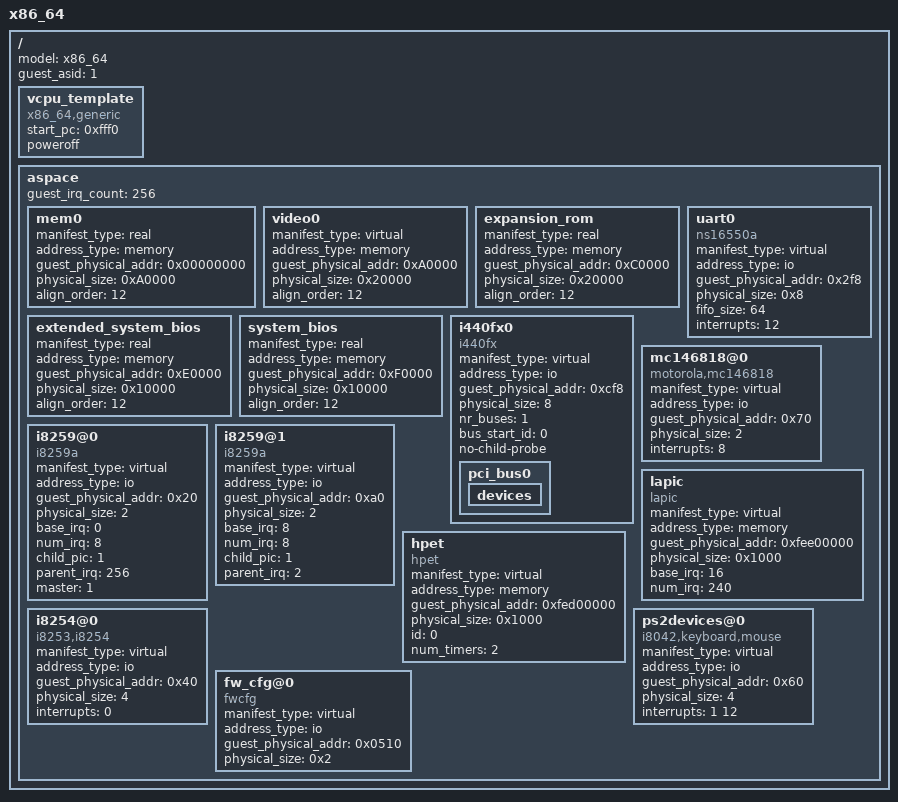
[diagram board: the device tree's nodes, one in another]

/dts-v1/;

/ {
	model = "x86_64";
	device_type = "guest";
	guest_asid = <1>;

	vcpu_template {
		device_type = "vcpu";
		compatible = "x86_64,generic";
		start_pc = <0xfff0>;
		poweroff;
	};

	aspace {
		guest_irq_count = <256>;
		/*
		 * Memory Regions
		 *
		 *   0 - 640 KiB => Accessible RAM (old DOS area)
		 * 640 - 768 KiB => Legacy Video card memory
		 * 768 - 896 KiB => Expansion area (Old peripheral card ROM)
		 * 896 - 960 KiB => Extended System BIOS (SeaBIOS links here 0xexxxx)
		 * 960 -   1 MiB => System BIOS
		 * 1MiB -  4GiB-16bytes => RAM (High Memory)
		 * 4GiB-16 byte => RESET VECTOR (0xFFFFFFF0) This jumps to System BIOS (normal/extented).
		 */

		/*
		 *	0x00000000 	0x000003FF 	1 KiB 		Real Mode IVT (Interrupt Vector Table)
		 *	0x00000400 	0x000004FF 	256 bytes 	BDA (BIOS data area)
		 *	0x00000500 	0x00007BFF 	30 KiB 		Conventional memory
		 *	0x00007C00  	0x00007DFF 	512 bytes 	OS BootSector
		 *	0x00007E00 	0x0007FFFF 	480.5 KiB 	Conventional memory
		 *	0x00080000 	0x0009FBFF 	~120 KiB 	Conventional memory
		 *	0x0009FC00 	0x0009FFFF 	1 KiB 		EBDA (Extended BIOS Data Area)
		 */
		mem0 {
			manifest_type = "real";
			address_type = "memory";
			guest_physical_addr = <0x00000000>;
			physical_size = <0xA0000>;
			device_type = "alloced_ram";
			align_order = <12>; /* 4K alignment */
		};

		video0 {
			manifest_type = "virtual";
			address_type = "memory";
			guest_physical_addr = <0xA0000>;
			physical_size = <0x20000>;
			device_type = "alloced_ram";
			align_order = <12>;
		};

		/* ROMs for old peripheral cards */
		expansion_rom {
			manifest_type = "real";
			address_type = "memory";
			guest_physical_addr = <0xC0000>;
			physical_size = <0x20000>;
			device_type = "alloced_rom";
			align_order = <12>;
		};

		/* Map in protected mode where BIOS will jump, Total 128K for BIOS */
		extended_system_bios {
			manifest_type = "real";
			address_type = "memory";
			guest_physical_addr = <0xE0000>;
			physical_size = <0x10000>; /* 64K extended BIOS */
			device_type = "alloced_rom";
			align_order = <12>; /* 4K aligns */
		};

		system_bios {
			manifest_type = "real";
			address_type = "memory";
			guest_physical_addr = <0xF0000>;
			physical_size = <0x10000>; /* 64K system BIOS */
			device_type = "alloced_rom";
			align_order = <12>;
		};

		uart0 {
			device_type = "serial";
			compatible = "ns16550a";
			manifest_type = "virtual";
			address_type = "io";
			guest_physical_addr = <0x2f8>;
			physical_size = <0x8>;
			fifo_size = <64>;
			interrupts = <12>;
		};

		i440fx0 {
			device_type = "pci-host-controller";
			compatible = "i440fx";
			manifest_type = "virtual";
			address_type = "io";
			guest_physical_addr = <0xcf8>;
			physical_size = <8>;
			nr_buses = <1>;
			bus_start_id = <0>;
			no-child-probe;

			pci_bus0 {
				devices {
				};
			};
		};

		mc146818@0 {
			device_type = "rtc";
			compatible = "motorola,mc146818";
			manifest_type = "virtual";
			address_type = "io";
			guest_physical_addr = <0x70>;
			physical_size = <2>;
			interrupts = <8>;
		};

		i8259@0 {
			device_type = "pic";
			compatible = "i8259a";
			manifest_type = "virtual";
			address_type = "io";
			guest_physical_addr = <0x20>;
			physical_size = <2>;
			base_irq = <0>;
			num_irq = <8>;
			child_pic = <1>;
			parent_irq = <256>; /* vector 16 to be presented on LAPIC */
			master = <1>;
		};

		i8259@1 {
			device_type = "pic";
			compatible = "i8259a";
			manifest_type = "virtual";
			address_type = "io";
			guest_physical_addr = <0xa0>;
			physical_size = <2>;
			base_irq = <8>;
			num_irq = <8>;
			child_pic = <1>;
			parent_irq = <2>;
		};


		lapic {
			device_type = "pic";
			compatible = "lapic";
			manifest_type = "virtual";
			address_type = "memory";
			guest_physical_addr = <0xfee00000>;
			physical_size = <0x1000>;
			base_irq = <16>;
			num_irq = <240>;
		};

		hpet {
			device_type = "hpet";
			compatible = "hpet";
			manifest_type = "virtual";
			address_type = "memory";
			guest_physical_addr = <0xfed00000>;
			physical_size = <0x1000>;
			id = <0>;
			num_timers = <2>;
		};

		i8254@0 {
			device_type = "pit";
			compatible = "i8253,i8254";
			manifest_type = "virtual";
			address_type = "io";
			guest_physical_addr = <0x40>;
			physical_size = <4>;
			interrupts = <0>;
		};

		ps2devices@0 {
			device_type = "input";
			compatible = "i8042,keyboard,mouse";
			manifest_type = "virtual";
			address_type = "io";
			guest_physical_addr = <0x60>;
			physical_size = <4>;
			interrupts = <1 12>;
		};

		fw_cfg@0 {
			device_type = "misc";
			compatible = "fwcfg";
			manifest_type = "virtual";
			address_type = "io";
			guest_physical_addr = <0x0510>;
			physical_size = <0x2>;
		};
	};
};
